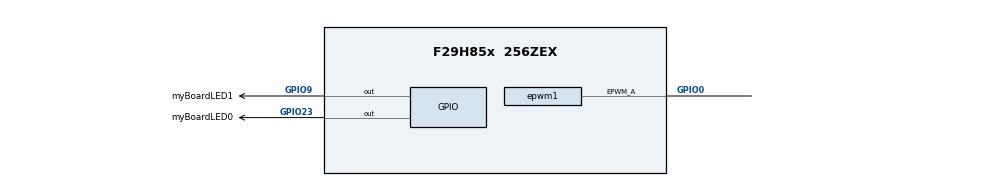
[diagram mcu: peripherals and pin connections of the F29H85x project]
/**
 * @cliArgs --device "F29H85x" --package "256ZEX" --part "F29H85x_256ZEX" --context "CPU1" --product "MCU_SDK_F29H85x@1.00.00.00"
 * @versions {"tool":"1.22.0+3877"}
 */

const divider15       = system.clockTree["PLL_REFDIV"];
divider15.divideValue = 1;

const multiplier1         = system.clockTree["PLL_IMULT"];
multiplier1.multiplyValue = 40;

const mux7       = system.clockTree["OSCCLKSRCSEL"];
mux7.inputSelect = "INTOSC2";

/**
 * Import the modules used in this configuration.
 */
const TILE                             = scripting.addModule("/clb_syscfg/source/TILE");
const TILE1                            = TILE.addInstance();
const clb_run_dynamic_template_clb_c   = scripting.addModule("/clb_syscfg/source/clb_run_dynamic_template_clb_c.js");
const clb_run_dynamic_template_clb_dot = scripting.addModule("/clb_syscfg/source/clb_run_dynamic_template_clb_dot.js");
const clb_run_dynamic_template_clb_h   = scripting.addModule("/clb_syscfg/source/clb_run_dynamic_template_clb_h.js");
const clb_run_dynamic_template_clb_sim = scripting.addModule("/clb_syscfg/source/clb_run_dynamic_template_clb_sim.js");
const led                              = scripting.addModule("/driverlib/board_components/led", {}, false);
const led1                             = led.addInstance();
const led2                             = led.addInstance();
const clb                              = scripting.addModule("/driverlib/clb.js", {}, false);
const clb1                             = clb.addInstance();
const clbxbar                          = scripting.addModule("/driverlib/clbxbar.js", {}, false);
const clbxbar1                         = clbxbar.addInstance();
const epwm                             = scripting.addModule("/driverlib/epwm.js", {}, false);
const epwm1                            = epwm.addInstance();
const inputxbar_input                  = scripting.addModule("/driverlib/inputxbar_input.js");
const inputxbar_input1                 = inputxbar_input.addInstance();

/**
 * Write custom configuration values to the imported modules.
 */
led1.$name                = "myBoardLED0";
led1.gpio.$name           = "LED_EPWM_GPIO";
led1.gpio.gpioPin.$assign = "GPIO23";

led2.$name                = "myBoardLED1";
led2.gpio.$name           = "LED_SENSOR_GPIO";
led2.gpio.gpioPin.$assign = "GPIO9";

clb1.$name                       = "myCLB1";
clb1.inputsUsed                  = ["CLB_IN0","CLB_IN1"];
clb1.inputTypeCLB_IN0            = "GLOBAL";
clb1.inputTypeCLB_IN1            = "GLOBAL";
clb1.globalConfigCLB_IN1         = "CLB_GLOBAL_IN_MUX_CLB_AUXSIG0";
clb1.synchronizeCLB_IN1          = true;
clb1.synchronizeCLB_IN0          = true;
clb1.outputsToOverridePeripheral = ["CLB_OUT0"];
clb1.enableCLB                   = true;
clb1.attachTile                  = true;
clb1.initTile                    = true;
clb1.periphClock.$name           = "driverlib_perClock0";
clb1.periphConfig.$name          = "driverlib_perConfig0";

clb1.tile                    = TILE1;
TILE1.$name                  = "TILE1";
TILE1.BOUNDARY.$name         = "BOUNDARY0";
TILE1.LUT_0.$name            = "LUT_0";
TILE1.LUT_1.$name            = "LUT_1";
TILE1.LUT_1.i0               = "BOUNDARY.in0";
TILE1.LUT_1.eqn              = "i0 & !i1";
TILE1.LUT_1.i1               = "BOUNDARY.in1";
TILE1.LUT_2.$name            = "LUT_2";
TILE1.LUT_2.i0               = "BOUNDARY.in1";
TILE1.LUT_2.eqn              = "!i0";
TILE1.FSM_0.$name            = "FSM_0";
TILE1.FSM_1.$name            = "FSM_1";
TILE1.FSM_2.$name            = "FSM_2";
TILE1.COUNTER_0.$name        = "COUNTER_0";
TILE1.COUNTER_1.$name        = "COUNTER_1";
TILE1.COUNTER_2.$name        = "COUNTER_2";
TILE1.OUTLUT_0.$name         = "OUTLUT_0";
TILE1.OUTLUT_0.eqn           = "i0";
TILE1.OUTLUT_0.i0            = "LUT_1.OUT";
TILE1.OUTLUT_1.$name         = "OUTLUT_1";
TILE1.OUTLUT_2.$name         = "OUTLUT_2";
TILE1.OUTLUT_3.$name         = "OUTLUT_3";
TILE1.OUTLUT_4.$name         = "OUTLUT_4";
TILE1.OUTLUT_5.$name         = "OUTLUT_5";
TILE1.OUTLUT_6.$name         = "OUTLUT_6";
TILE1.OUTLUT_7.$name         = "OUTLUT_7";
TILE1.HLC.$name              = "HLC_0";
TILE1.HLC.e0                 = "BOUNDARY.in1";
TILE1.HLC.e1                 = "LUT_2.OUT";
TILE1.HLC.program0.$name     = "HLCP_0";
TILE1.HLC.program0.instruct0 = "INTR 1";
TILE1.HLC.program1.$name     = "HLCP_1";
TILE1.HLC.program1.instruct0 = "INTR 2";
TILE1.HLC.program2.$name     = "HLCP_2";
TILE1.HLC.program3.$name     = "HLCP_3";
TILE1.AOC_0.$name            = "AOC_0";
TILE1.AOC_1.$name            = "AOC_1";
TILE1.AOC_2.$name            = "AOC_2";
TILE1.AOC_3.$name            = "AOC_3";
TILE1.AOC_4.$name            = "AOC_4";
TILE1.AOC_5.$name            = "AOC_5";
TILE1.AOC_6.$name            = "AOC_6";
TILE1.AOC_7.$name            = "AOC_7";

clbxbar1.$name         = "myCLBXBAR0";
clbxbar1.sourceSignals = ["INPUTXBAR_INPUT1"];

epwm1.$name                                                      = "myEPWM1";
epwm1.epwmTimebase_hsClockDiv                                    = "EPWM_HSCLOCK_DIVIDER_1";
epwm1.epwmTimebase_period                                        = 25000;
epwm1.epwmTimebase_counterMode                                   = "EPWM_COUNTER_MODE_UP_DOWN";
epwm1.epwmCounterCompare_cmpA                                    = 12500;
epwm1.epwmActionQualifier_EPWM_AQ_OUTPUT_A_shadowMode            = true;
epwm1.epwmActionQualifier_EPWM_AQ_OUTPUT_A_ON_TIMEBASE_UP_CMPA   = "EPWM_AQ_OUTPUT_HIGH";
epwm1.epwmActionQualifier_EPWM_AQ_OUTPUT_A_ON_TIMEBASE_DOWN_CMPA = "EPWM_AQ_OUTPUT_LOW";
epwm1.useCase                                                    = "CUSTOM";
epwm1.useInterfacePins                                           = ["EPWM#_A"];
epwm1.periphClock.$name                                          = "driverlib_perClock1";
epwm1.periphConfig.$name                                         = "driverlib_perConfig1";
epwm1.epwm.$assign                                               = "EPWM1";
epwm1.epwm.epwm_aPin.$assign                                     = "GPIO0";

inputxbar_input1.$name         = "myINPUTXBARINPUT0";
inputxbar_input1.inputxbarGpio = "GPIO27";
